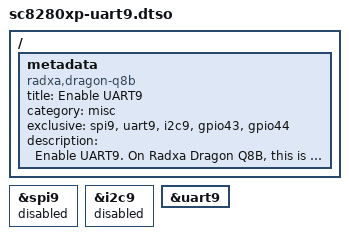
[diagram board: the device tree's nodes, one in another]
// SPDX-License-Identifier: BSD-3-Clause
/*
 * Copyright (c) 2026 Radxa Computer (Shenzhen) Co., Ltd.
 */

/dts-v1/;
/plugin/;

/ {
	metadata {
		title = "Enable UART9";
		compatible = "radxa,dragon-q8b";
		category = "misc";
		exclusive = "spi9", "uart9", "i2c9", "gpio43", "gpio44";
		description = "Enable UART9.
On Radxa Dragon Q8B, this is pin 27(tx), 28(rx).";
	};
};

&spi9 {
	status = "disabled";
};

&i2c9 {
	status = "disabled";
};

&uart9 {
	status = "okay";
};
